# COMPUTE_CLUSTER0_CLEC_CLEC register map
Vendor: Texas Instruments
Peripheral module from a debugger description file (folder J721S2).
Registers are 32-bit, read-only, reset values left out (the file's numbers can be read two ways) unless marked. A register's access mark holds for its fields unless they carry their own. Offsets are as the file gives them; lines under a group give offsets from that group; [hi:lo] are bit positions; {n}, {i} and the like mark numbered series; 'fields as' and 'values as' point back to an identical list; <NAME> marks a mode.

## COMPUTE_CLUSTER0_CLEC_CLEC
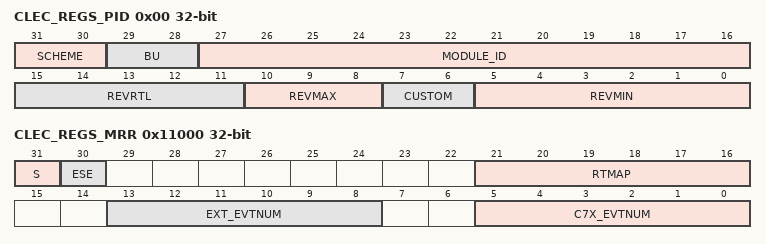
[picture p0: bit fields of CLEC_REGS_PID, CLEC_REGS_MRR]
0x00 CLEC_REGS_PID — Revision parameters
  [31:30] SCHEME
  [29:28] BU — Scheme
  [27:16] MODULE_ID
  [15:11] REVRTL — RTL version
  [10:8] REVMAX — Major version
  [7:6] CUSTOM — Custom version
  [5:0] REVMIN — Minor version
0xA000 CLEC_REGS_EFR — CLEC event flags
  [31:0] EVNTFR — event flags
0xB000 CLEC_REGS_EDR — CLEC dropped event flags
  [31:0] EVNTFR — dropped event flags
0xC000 CLEC_REGS_GELRS rw — Event Lock reg for secure claim
  [0] LOCK — GELRS.LOCK
0xD000 CLEC_REGS_GELRNS rw — Event Lock reg for non-secure claim
  [0] LOCK — GELRNS.LOCK
0x11000 CLEC_REGS_MRR rw — Map and routing register
  [31] S — MRR.S
  [30] ESE — MRR.ESE
  [21:16] RTMAP — MRR.EXT_EVTNUM
  [13:8] EXT_EVTNUM — MRR.EXT_EVTNUM
  [5:0] C7X_EVTNUM — MRR.C7x_EVTNUM
0x13000 CLEC_REGS_ESR access not given — Event send reg
0x14000 CLEC_REGS_ECR access not given — Event clear reg
